VERSION ""

NS_ :

BS_:

BU_: CLUSTER INVERTER

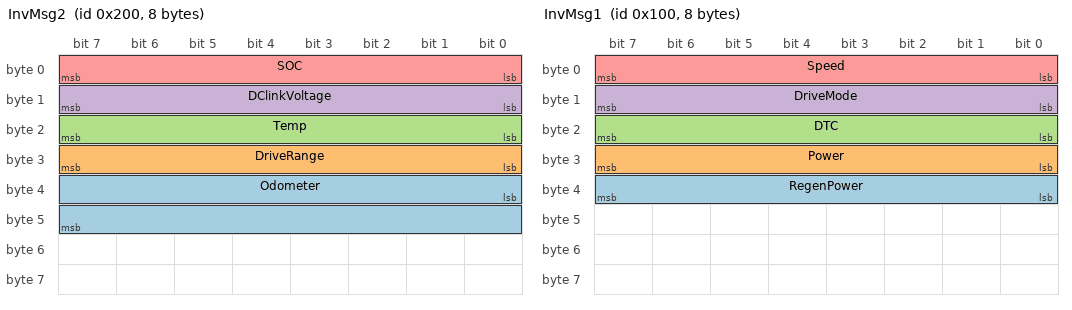
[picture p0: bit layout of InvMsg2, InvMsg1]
BO_ 512 InvMsg2: 8 INVERTER
 SG_ Odometer : 32|16@1+ (5,0) [0|327675] "km"  CLUSTER
 SG_ DriveRange : 24|8@1+ (1,0) [0|255] "km"  CLUSTER
 SG_ Temp : 16|8@1+ (1,-20) [-20|235] "degC"  CLUSTER
 SG_ DClinkVoltage : 8|8@1+ (1,0) [0|80] "V"  CLUSTER
 SG_ SOC : 0|8@1+ (1,0) [0|100] "%"  CLUSTER

BO_ 256 InvMsg1: 8 INVERTER
 SG_ RegenPower : 32|8@1+ (1,0) [0|255] "kW"  CLUSTER
 SG_ Power : 24|8@1+ (1,0) [0|255] "kW"  CLUSTER
 SG_ DTC : 16|8@1+ (1,0) [0|255] ""  CLUSTER
 SG_ DriveMode : 8|8@1+ (1,0) [0|3] ""  CLUSTER
 SG_ Speed : 0|8@1+ (1,-10) [-10|245] "km/h"  CLUSTER

EV_ EnvKlemme30: 0 [0|1] "" 1 1 DUMMY_NODE_VECTOR0 Vector__XXX;

EV_ EnvKlemme15: 0 [0|1] "" 0 2 DUMMY_NODE_VECTOR0 Vector__XXX;

BA_DEF_ BU_  "NodeLayerModules" STRING ;
BA_DEF_ BO_  "GenMsgILSupport" ENUM  "No","Yes";
BA_DEF_  "NmBaseAddress" HEX 1024 1087;
BA_DEF_  "BusType" STRING ;
BA_DEF_ BO_  "GenMsgCycleTime" INT 0 50000;
BA_DEF_ BO_  "GenMsgSendType" ENUM  "Cyclic","NotUsed","NotUsed","NotUsed","NotUsed","NotUsed","NotUsed","IfActive","NoMsgSendType","NotUsed","vector_leerstring";
BA_DEF_ SG_  "GenSigSendType" ENUM  "Cyclic","OnWrite","OnWriteWithRepetition","OnChange","OnChangeWithRepetition","IfActive","IfActiveWithRepetition","NoSigSendType","NotUsed","NotUsed","NotUsed","NotUsed","NotUsed";
BA_DEF_ SG_  "GenSigStartValue" FLOAT 0 100000000000;
BA_DEF_DEF_  "NodeLayerModules" "CANoeILNLVector.dll";
BA_DEF_DEF_  "GenMsgILSupport" "Yes";
BA_DEF_DEF_  "NmBaseAddress" 1024;
BA_DEF_DEF_  "BusType" "";
BA_DEF_DEF_  "GenMsgCycleTime" 0;
BA_DEF_DEF_  "GenMsgSendType" "NoMsgSendType";
BA_DEF_DEF_  "GenSigSendType" "Cyclic";
BA_DEF_DEF_  "GenSigStartValue" 0;
BA_ "BusType" "CAN";
BA_ "GenMsgCycleTime" BO_ 512 200;
BA_ "GenMsgCycleTime" BO_ 256 100;
BA_ "GenSigStartValue" SG_ 512 Temp 20;
BA_ "GenSigStartValue" SG_ 256 Speed 10;
VAL_ 256 DriveMode 0 "P" 1 "R" 2 "N" 3 "D" ;

CM_ "See docs/design/can-signals.md in the project git repo for full rationale (message priority grouping, Odometer compression, byte layout). Kept ASCII-only here for CAN tool compatibility (CANdb++ does not support UTF-8).";
